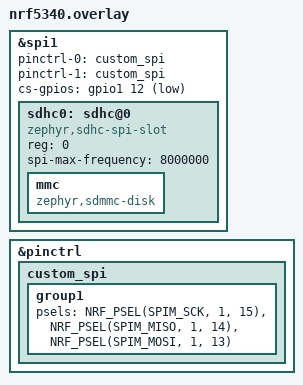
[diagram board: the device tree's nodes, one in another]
&spi1 {
	status = "okay";
	pinctrl-0 = <&custom_spi>;
	pinctrl-1 = <&custom_spi>;
	pinctrl-names = "default", "sleep";
	cs-gpios = <&gpio1 12 GPIO_ACTIVE_LOW>;

	sdhc0: sdhc@0 {
		compatible = "zephyr,sdhc-spi-slot";
		reg = <0>;
		status = "okay";
		mmc {
			compatible = "zephyr,sdmmc-disk";
			status = "okay";
		};
		spi-max-frequency = <8000000>;
	};
};

&pinctrl {
	custom_spi: custom_spi {
		group1 {
			psels = <NRF_PSEL(SPIM_SCK, 1, 15)>,
                <NRF_PSEL(SPIM_MISO, 1, 14)>,
                <NRF_PSEL(SPIM_MOSI, 1, 13)>;
		};
	};
};
